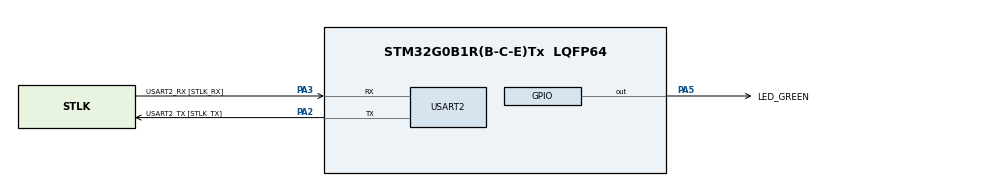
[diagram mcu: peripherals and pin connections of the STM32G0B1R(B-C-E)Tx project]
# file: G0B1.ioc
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FREERTOS.Tasks01=defaultTask,0,128,StartDefaultTask,Default,NULL,Dynamic,NULL,NULL;myTask02_Diagno,-3,128,StartTask02,Default,NULL,Dynamic,NULL,NULL;myTask03_Deferr,-3,128,StartTask03,Default,NULL,Dynamic,NULL,NULL
Mcu.Family=STM32G0
Mcu.Name=STM32G0B1R(B-C-E)Tx
Mcu.Package=LQFP64
NVIC.TIM17_FDCAN_IT1_IRQn=true\:3\:0\:false\:false\:true\:false\:true\:true\:true
NVIC.TimeBase=TIM17_FDCAN_IT1_IRQn
NVIC.TimeBaseIP=TIM17
PA13.GPIO_Label=TMS
PA13.Mode=Serial_Wire
PA13.Signal=SYS_SWDIO
PA14-BOOT0.GPIO_Label=TCK
PA14-BOOT0.Mode=Serial_Wire
PA14-BOOT0.Signal=SYS_SWCLK
PA2.GPIO_Label=USART2_TX [STLK_TX]
PA2.Mode=Asynchronous
PA2.Signal=USART2_TX
PA3.GPIO_Label=USART2_RX [STLK_RX]
PA3.Mode=Asynchronous
PA3.Signal=USART2_RX
PA5.GPIO_Label=LED_GREEN
PA5.GPIO_Speed=GPIO_SPEED_FREQ_HIGH
PA5.Signal=GPIO_Output
PC13.Mode=SYS_WakeUp1
PC13.Signal=SYS_WKUP2
PC14-OSC32_IN\ (PC14).Mode=LSE-External-Oscillator
PC14-OSC32_IN\ (PC14).Signal=RCC_OSC32_IN
PC15-OSC32_OUT\ (PC15).Mode=LSE-External-Oscillator
PC15-OSC32_OUT\ (PC15).Signal=RCC_OSC32_OUT
PF0-OSC_IN\ (PF0).GPIO_Label=MCO
PF0-OSC_IN\ (PF0).Mode=HSE-External-Clock-Source
PF0-OSC_IN\ (PF0).Signal=RCC_OSC_IN
ProjectManager.HeapSize=0x200
ProjectManager.StackSize=0x400
ProjectManager.TargetToolchain=Makefile
RCC.AHBFreq_Value=16000000
RCC.CortexFreq_Value=16000000
RCC.EXTERNAL_CLOCK_VALUE=12288000
RCC.HCLKFreq_Value=16000000
RCC.HSE_VALUE=8000000
RCC.HSI48_VALUE=48000000
RCC.HSI_VALUE=16000000
RCC.SYSCLKFreq_VALUE=16000000
RCC.USBFreq_Value=48000000
RCC.VCOOutputFreq_Value=128000000
USART2.VirtualMode-Asynchronous=VM_ASYNC
VP_FREERTOS_VS_CMSIS_V1.Mode=CMSIS_V1
VP_SYS_VS_tim17.Mode=TIM17
board=NUCLEO-G0B1RE

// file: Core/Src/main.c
/* USER CODE BEGIN Header */
/**
 ******************************************************************************
 * @file           : main.c
 * @brief          : Main program body
 ******************************************************************************
 * @attention
 *
 * Copyright (c) 2023 STMicroelectronics.
 * All rights reserved.
 *
 * This software is licensed under terms that can be found in the LICENSE file
 * in the root directory of this software component.
 * If no LICENSE file comes with this software, it is provided AS-IS.
 *
 ******************************************************************************
 */
/* USER CODE END Header */
#include "main.h"
#include "cmsis_os.h"

/* USER CODE BEGIN Includes */
#include "trice.h"
/* USER CODE END Includes */

osThreadId defaultTaskHandle;
osThreadId myTask02_DiagnoHandle;
osThreadId myTask03_DeferrHandle;
/* USER CODE BEGIN PV */
int LoopCount = 0;

/* USER CODE END PV */

void SystemClock_Config(void);
static void MX_GPIO_Init(void);
static void MX_USART2_UART_Init(void);
void StartDefaultTask(void const * argument);
void StartTask02(void const * argument);
void StartTask03(void const * argument);

int main(void)
{

  /* MCU Configuration--------------------------------------------------------*/

  /* Reset of all peripherals, Initializes the Flash interface and the Systick. */
  HAL_Init();

  /* Configure the system clock */
  SystemClock_Config();

  /* USER CODE BEGIN SysInit */
    TriceInit();

    //! This is usable as the very first trice sequence after restart. Adapt it. Use a UTF-8 capable editor like VS-Code or use pure ASCII.
    trice( "\n\n        ✨✨✨✨✨✨✨✨✨✨✨✨✨✨✨✨✨        \n        🎈🎈🎈🎈     NUCLEO-G0B1RE      🎈🎈🎈🎈\n        ✨✨✨✨✨✨✨✨✨✨✨✨✨✨✨✨✨        \n\n\n");
    TRice( "w: Hello! 👋🙂\a\n" ); // with sound!

/*
    TRICE_S( id(0), "wr:%s\n", "\n" );
    TRICE_S( id(0), "wr:%s\n", "A\n" );
    TRICE_S( id(0), "wr:%s\n", "AA\n" );
    TRICE_S( id(0), "wr:%s\n", "AAA\n" );
    TRICE_S( id(0), "wr:%s\n", "AAAA\n" );
    TRICE_S( id(0), "wr:%s\n", "AAAAA\n" );
    TRICE_S( id(0), "wr:%s\n", "AAAAAA\n" );
    TRICE_S( id(0), "wr:%s\n", "AAAAAAA\n" );
    TRICE_S( id(0), "wr:%s\n", "AAAAAAAA\n" );
    TRICE_S( id(0), "wr:%s\n", "AAAAAAAAA\n" );
    TRICE_S( id(0), "wr:%s\n", "AAAAAAAAAA\n" );
    TRICE_S( id(0), "wr:%s\n", "AAAAAAAAAAA\n" );
    TRICE_S( id(0), "wr:%s\n", "AAAAAAAAAAAA\n" );
    TRICE_S( id(0), "wr:%s\n", "AAAAAAAAAAAAA\n" );
    TRICE_S( id(0), "wr:%s\n", "AAAAAAAAAAAAAA\n" );
    TRICE_S( id(0), "wr:%s\n", "AAAAAAAAAAAAAAA\n" );
    TRICE_S( id(0), "wr:%s\n", "AAAAAAAAAAAAAAAA\n" );
    TRICE_S( id(0), "wr:%s\n", "AAAAAAAAAAAAAAAAA\n" );
    TRICE_S( id(0), "wr:%s\n", "AAAAAAAAAAAAAAAAAA\n" );
    TRICE_S( id(0), "wr:%s\n", "AAAAAAAAAAAAAAAAAAA\n" );
    TRICE_S( id(0), "wr:%s\n", "AAAAAAAAAAAAAAAAAAAA\n" );
    TRICE_S( id(0), "wr:%s\n", "AAAAAAAAAAAAAAAAAAAAA\n" );
    TRICE_S( id(0), "wr:%s\n", "AAAAAAAAAAAAAAAAAAAAAA\n" );
    TRICE_S( id(0), "wr:%s\n", "AAAAAAAAAAAAAAAAAAAAAAA\n" );
    TRICE_S( id(0), "wr:%s\n", "AAAAAAAAAAAAAAAAAAAAAAAA\n" );
    TRICE_S( id(0), "wr:%s\n", "AAAAAAAAAAAAAAAAAAAAAAAAA\n" );
    TRICE_S( id(0), "wr:%s\n", "AAAAAAAAAAAAAAAAAAAAAAAAAA\n" );
    TRICE_S( id(0), "wr:%s\n", "AAAAAAAAAAAAAAAAAAAAAAAAAAA\n" );
    TRICE_S( id(0), "wr:%s\n", "AAAAAAAAAAAAAAAAAAAAAAAAAAAA\n" );
    TRICE_S( id(0), "wr:%s\n", "AAAAAAAAAAAAAAAAAAAAAAAAAAAAA\n" );
    TRICE_S( id(0), "wr:%s\n", "AAAAAAAAAAAAAAAAAAAAAAAAAAAAAA\n" );
    TRICE_S( id(0), "wr:%s\n", "AAAAAAAAAAAAAAAAAAAAAAAAAAAAAAA\n" );
    TRICE_S( id(0), "wr:%s\n", "AAAAAAAAAAAAAAAAAAAAAAAAAAAAAAAA\n" );
    TRICE_S( id(0), "wr:%s\n", "AAAAAAAAAAAAAAAAAAAAAAAAAAAAAAAAA\n" );
    TRICE_S( id(0), "wr:%s\n", "AAAAAAAAAAAAAAAAAAAAAAAAAAAAAAAAAA\n" );
    TRICE_S( id(0), "wr:%s\n", "AAAAAAAAAAAAAAAAAAAAAAAAAAAAAAAAAAA\n" );
    TRICE_S( id(0), "wr:%s\n", "AAAAAAAAAAAAAAAAAAAAAAAAAAAAAAAAAAAA\n" );
    TRICE_S( id(0), "wr:%s\n", "AAAAAAAAAAAAAAAAAAAAAAAAAAAAAAAAAAAAA\n" );
    TRICE_S( id(0), "wr:%s\n", "AAAAAAAAAAAAAAAAAAAAAAAAAAAAAAAAAAAAAA\n" );
    TRICE_S( id(0), "wr:%s\n", "AAAAAAAAAAAAAAAAAAAAAAAAAAAAAAAAAAAAAAA\n" );
    TRICE_S( id(0), "wr:%s\n", "AAAAAAAAAAAAAAAAAAAAAAAAAAAAAAAAAAAAAAAA\n" );
    TRICE_S( id(0), "wr:%s\n", "AAAAAAAAAAAAAAAAAAAAAAAAAAAAAAAAAAAAAAAAA\n" );
    TRICE_S( id(0), "wr:%s\n", "AAAAAAAAAAAAAAAAAAAAAAAAAAAAAAAAAAAAAAAAAA\n" );
    TRICE_S( id(0), "wr:%s\n", "AAAAAAAAAAAAAAAAAAAAAAAAAAAAAAAAAAAAAAAAAAA\n" );
    TRICE_S( id(0), "wr:%s\n", "AAAAAAAAAAAAAAAAAAAAAAAAAAAAAAAAAAAAAAAAAAAA\n" );
    TRICE_S( id(0), "wr:%s\n", "AAAAAAAAAAAAAAAAAAAAAAAAAAAAAAAAAAAAAAAAAAAAA\n" );
    TRICE_S( id(0), "wr:%s\n", "AAAAAAAAAAAAAAAAAAAAAAAAAAAAAAAAAAAAAAAAAAAAAA\n" );
    TRICE_S( id(0), "wr:%s\n", "AAAAAAAAAAAAAAAAAAAAAAAAAAAAAAAAAAAAAAAAAAAAAAA\n" );
    TRICE_S( id(0), "wr:%s\n", "AAAAAAAAAAAAAAAAAAAAAAAAAAAAAAAAAAAAAAAAAAAAAAAA\n" );
    TRICE_S( id(0), "wr:%s\n", "AAAAAAAAAAAAAAAAAAAAAAAAAAAAAAAAAAAAAAAAAAAAAAAAA\n" );
    TRICE_S( id(0), "wr:%s\n", "AAAAAAAAAAAAAAAAAAAAAAAAAAAAAAAAAAAAAAAAAAAAAAAAAA\n" );
    TRICE_S( id(0), "wr:%s\n", "AAAAAAAAAAAAAAAAAAAAAAAAAAAAAAAAAAAAAAAAAAAAAAAAAAA\n" );
    TRICE_S( id(0), "wr:%s\n", "AAAAAAAAAAAAAAAAAAAAAAAAAAAAAAAAAAAAAAAAAAAAAAAAAAAA\n" );
    TRICE_S( id(0), "wr:%s\n", "AAAAAAAAAAAAAAAAAAAAAAAAAAAAAAAAAAAAAAAAAAAAAAAAAAAAA\n" );
    TRICE_S( id(0), "wr:%s\n", "AAAAAAAAAAAAAAAAAAAAAAAAAAAAAAAAAAAAAAAAAAAAAAAAAAAAAA\n" );
    TRICE_S( id(0), "wr:%s\n", "AAAAAAAAAAAAAAAAAAAAAAAAAAAAAAAAAAAAAAAAAAAAAAAAAAAAAAA\n" );
    TRICE_S( id(0), "wr:%s\n", "AAAAAAAAAAAAAAAAAAAAAAAAAAAAAAAAAAAAAAAAAAAAAAAAAAAAAAAA\n" );
    TRICE_S( id(0), "wr:%s\n", "AAAAAAAAAAAAAAAAAAAAAAAAAAAAAAAAAAAAAAAAAAAAAAAAAAAAAAAAA\n" );
    TRICE_S( id(0), "wr:%s\n", "AAAAAAAAAAAAAAAAAAAAAAAAAAAAAAAAAAAAAAAAAAAAAAAAAAAAAAAAAA\n" );
    TRICE_S( id(0), "wr:%s\n", "AAAAAAAAAAAAAAAAAAAAAAAAAAAAAAAAAAAAAAAAAAAAAAAAAAAAAAAAAAA\n" );
    TRICE_S( id(0), "wr:%s\n", "AAAAAAAAAAAAAAAAAAAAAAAAAAAAAAAAAAAAAAAAAAAAAAAAAAAAAAAAAAAA\n" );
    TRICE_S( id(0), "wr:%s\n", "AAAAAAAAAAAAAAAAAAAAAAAAAAAAAAAAAAAAAAAAAAAAAAAAAAAAAAAAAAAAA\n" );
    TRICE_S( id(0), "wr:%s\n", "AAAAAAAAAAAAAAAAAAAAAAAAAAAAAAAAAAAAAAAAAAAAAAAAAAAAAAAAAAAAAA\n" );
    TRICE_S( id(0), "wr:%s\n", "AAAAAAAAAAAAAAAAAAAAAAAAAAAAAAAAAAAAAAAAAAAAAAAAAAAAAAAAAAAAAAA\n" );
    TRICE_S( id(0), "wr:%s\n", "AAAAAAAAAAAAAAAAAAAAAAAAAAAAAAAAAAAAAAAAAAAAAAAAAAAAAAAAAAAAAAAA\n" );
    TRICE_S( id(0), "wr:%s\n", "AAAAAAAAAAAAAAAAAAAAAAAAAAAAAAAAAAAAAAAAAAAAAAAAAAAAAAAAAAAAAAAAA\n" );
    TRICE_S( id(0), "wr:%s\n", "AAAAAAAAAAAAAAAAAAAAAAAAAAAAAAAAAAAAAAAAAAAAAAAAAAAAAAAAAAAAAAAAAA\n" );
    TRICE_S( id(0), "wr:%s\n", "AAAAAAAAAAAAAAAAAAAAAAAAAAAAAAAAAAAAAAAAAAAAAAAAAAAAAAAAAAAAAAAAAAA\n" );
    TRICE_S( id(0), "wr:%s\n", "AAAAAAAAAAAAAAAAAAAAAAAAAAAAAAAAAAAAAAAAAAAAAAAAAAAAAAAAAAAAAAAAAAAA\n" );
    TRICE_S( id(0), "wr:%s\n", "AAAAAAAAAAAAAAAAAAAAAAAAAAAAAAAAAAAAAAAAAAAAAAAAAAAAAAAAAAAAAAAAAAAAA\n" );
    TRICE_S( id(0), "wr:%s\n", "AAAAAAAAAAAAAAAAAAAAAAAAAAAAAAAAAAAAAAAAAAAAAAAAAAAAAAAAAAAAAAAAAAAAAA\n" );
    TRICE_S( id(0), "wr:%s\n", "AAAAAAAAAAAAAAAAAAAAAAAAAAAAAAAAAAAAAAAAAAAAAAAAAAAAAAAAAAAAAAAAAAAAAAA\n" );
    TRICE_S( id(0), "wr:%s\n", "AAAAAAAAAAAAAAAAAAAAAAAAAAAAAAAAAAAAAAAAAAAAAAAAAAAAAAAAAAAAAAAAAAAAAAAA\n" );
    TRICE_S( id(0), "wr:%s\n", "AAAAAAAAAAAAAAAAAAAAAAAAAAAAAAAAAAAAAAAAAAAAAAAAAAAAAAAAAAAAAAAAAAAAAAAAA\n" );
    TRICE_S( id(0), "wr:%s\n", "AAAAAAAAAAAAAAAAAAAAAAAAAAAAAAAAAAAAAAAAAAAAAAAAAAAAAAAAAAAAAAAAAAAAAAAAAA\n" );
    TRICE_S( id(0), "wr:%s\n", "AAAAAAAAAAAAAAAAAAAAAAAAAAAAAAAAAAAAAAAAAAAAAAAAAAAAAAAAAAAAAAAAAAAAAAAAAAA\n" );
    TRICE_S( id(0), "wr:%s\n", "AAAAAAAAAAAAAAAAAAAAAAAAAAAAAAAAAAAAAAAAAAAAAAAAAAAAAAAAAAAAAAAAAAAAAAAAAAAA\n" );
    TRICE_S( id(0), "wr:%s\n", "AAAAAAAAAAAAAAAAAAAAAAAAAAAAAAAAAAAAAAAAAAAAAAAAAAAAAAAAAAAAAAAAAAAAAAAAAAAAA\n" );
    TRICE_S( id(0), "wr:%s\n", "AAAAAAAAAAAAAAAAAAAAAAAAAAAAAAAAAAAAAAAAAAAAAAAAAAAAAAAAAAAAAAAAAAAAAAAAAAAAAA\n" );
    TRICE_S( id(0), "wr:%s\n", "AAAAAAAAAAAAAAAAAAAAAAAAAAAAAAAAAAAAAAAAAAAAAAAAAAAAAAAAAAAAAAAAAAAAAAAAAAAAAAA\n" );
    TRICE_S( id(0), "wr:%s\n", "AAAAAAAAAAAAAAAAAAAAAAAAAAAAAAAAAAAAAAAAAAAAAAAAAAAAAAAAAAAAAAAAAAAAAAAAAAAAAAA\n" );
    TRICE_S( id(0), "wr:%s\n", "AAAAAAAAAAAAAAAAAAAAAAAAAAAAAAAAAAAAAAAAAAAAAAAAAAAAAAAAAAAAAAAAAAAAAAAAAAAAAAAA\n" );
    TRICE_S( id(0), "wr:%s\n", "AAAAAAAAAAAAAAAAAAAAAAAAAAAAAAAAAAAAAAAAAAAAAAAAAAAAAAAAAAAAAAAAAAAAAAAAAAAAAAAAA\n" );
    TRICE_S( id(0), "wr:%s\n", "AAAAAAAAAAAAAAAAAAAAAAAAAAAAAAAAAAAAAAAAAAAAAAAAAAAAAAAAAAAAAAAAAAAAAAAAAAAAAAAAAA\n" );
    TRICE_S( id(0), "wr:%s\n", "AAAAAAAAAAAAAAAAAAAAAAAAAAAAAAAAAAAAAAAAAAAAAAAAAAAAAAAAAAAAAAAAAAAAAAAAAAAAAAAAAAA\n" );
    TRICE_S( id(0), "wr:%s\n", "AAAAAAAAAAAAAAAAAAAAAAAAAAAAAAAAAAAAAAAAAAAAAAAAAAAAAAAAAAAAAAAAAAAAAAAAAAAAAAAAAAAA\n" );
    TRICE_S( id(0), "wr:%s\n", "AAAAAAAAAAAAAAAAAAAAAAAAAAAAAAAAAAAAAAAAAAAAAAAAAAAAAAAAAAAAAAAAAAAAAAAAAAAAAAAAAAAAA\n" );
    TRICE_S( id(0), "wr:%s\n", "AAAAAAAAAAAAAAAAAAAAAAAAAAAAAAAAAAAAAAAAAAAAAAAAAAAAAAAAAAAAAAAAAAAAAAAAAAAAAAAAAAAAAA\n" );
    TRICE_S( id(0), "wr:%s\n", "AAAAAAAAAAAAAAAAAAAAAAAAAAAAAAAAAAAAAAAAAAAAAAAAAAAAAAAAAAAAAAAAAAAAAAAAAAAAAAAAAAAAAAA\n" );
    TRICE_S( id(0), "wr:%s\n", "AAAAAAAAAAAAAAAAAAAAAAAAAAAAAAAAAAAAAAAAAAAAAAAAAAAAAAAAAAAAAAAAAAAAAAAAAAAAAAAAAAAAAAAA\n" );
    TRICE_S( id(0), "wr:%s\n", "AAAAAAAAAAAAAAAAAAAAAAAAAAAAAAAAAAAAAAAAAAAAAAAAAAAAAAAAAAAAAAAAAAAAAAAAAAAAAAAAAAAAAAAAA\n" );
    TRICE_S( id(0), "wr:%s\n", "AAAAAAAAAAAAAAAAAAAAAAAAAAAAAAAAAAAAAAAAAAAAAAAAAAAAAAAAAAAAAAAAAAAAAAAAAAAAAAAAAAAAAAAAAA\n" );
    TRICE_S( id(0), "wr:%s\n", "AAAAAAAAAAAAAAAAAAAAAAAAAAAAAAAAAAAAAAAAAAAAAAAAAAAAAAAAAAAAAAAAAAAAAAAAAAAAAAAAAAAAAAAAAAA\n" );
    TRICE_S( id(0), "wr:%s\n", "AAAAAAAAAAAAAAAAAAAAAAAAAAAAAAAAAAAAAAAAAAAAAAAAAAAAAAAAAAAAAAAAAAAAAAAAAAAAAAAAAAAAAAAAAAAA\n" );
    TRICE_S( id(0), "wr:%s\n", "AAAAAAAAAAAAAAAAAAAAAAAAAAAAAAAAAAAAAAAAAAAAAAAAAAAAAAAAAAAAAAAAAAAAAAAAAAAAAAAAAAAAAAAAAAAAA\n" );
    TRICE_S( id(0), "wr:%s\n", "AAAAAAAAAAAAAAAAAAAAAAAAAAAAAAAAAAAAAAAAAAAAAAAAAAAAAAAAAAAAAAAAAAAAAAAAAAAAAAAAAAAAAAAAAAAAAA\n" );
    TRICE_S( id(0), "wr:%s\n", "AAAAAAAAAAAAAAAAAAAAAAAAAAAAAAAAAAAAAAAAAAAAAAAAAAAAAAAAAAAAAAAAAAAAAAAAAAAAAAAAAAAAAAAAAAAAAAA\n" );
    TRICE_S( id(0), "wr:%s\n", "AAAAAAAAAAAAAAAAAAAAAAAAAAAAAAAAAAAAAAAAAAAAAAAAAAAAAAAAAAAAAAAAAAAAAAAAAAAAAAAAAAAAAAAAAAAAAAAA\n" );
    TRICE_S( id(0), "wr:%s\n", "AAAAAAAAAAAAAAAAAAAAAAAAAAAAAAAAAAAAAAAAAAAAAAAAAAAAAAAAAAAAAAAAAAAAAAAAAAAAAAAAAAAAAAAAAAAAAAAAA\n" );
    TRICE_S( id(0), "wr:%s\n", "AAAAAAAAAAAAAAAAAAAAAAAAAAAAAAAAAAAAAAAAAAAAAAAAAAAAAAAAAAAAAAAAAAAAAAAAAAAAAAAAAAAAAAAAAAAAAAAAAA\n" );
    TRICE_S( id(0), "wr:%s\n", "AAAAAAAAAAAAAAAAAAAAAAAAAAAAAAAAAAAAAAAAAAAAAAAAAAAAAAAAAAAAAAAAAAAAAAAAAAAAAAAAAAAAAAAAAAAAAAAAAAA\n" );
    TRICE_S( id(0), "wr:%s\n", "AAAAAAAAAAAAAAAAAAAAAAAAAAAAAAAAAAAAAAAAAAAAAAAAAAAAAAAAAAAAAAAAAAAAAAAAAAAAAAAAAAAAAAAAAAAAAAAAAAAA\n" );
    TRICE_S( id(0), "wr:%s\n", "AAAAAAAAAAAAAAAAAAAAAAAAAAAAAAAAAAAAAAAAAAAAAAAAAAAAAAAAAAAAAAAAAAAAAAAAAAAAAAAAAAAAAAAAAAAAAAAAAAAAA\n" );
    TRICE_S( id(0), "wr:%s\n", "AAAAAAAAAAAAAAAAAAAAAAAAAAAAAAAAAAAAAAAAAAAAAAAAAAAAAAAAAAAAAAAAAAAAAAAAAAAAAAAAAAAAAAAAAAAAAAAAAAAAAA\n" );
    TRICE_S( id(0), "wr:%s\n", "AAAAAAAAAAAAAAAAAAAAAAAAAAAAAAAAAAAAAAAAAAAAAAAAAAAAAAAAAAAAAAAAAAAAAAAAAAAAAAAAAAAAAAAAAAAAAAAAAAAAAAA\n" );
    TRICE_S( id(0), "wr:%s\n", "AAAAAAAAAAAAAAAAAAAAAAAAAAAAAAAAAAAAAAAAAAAAAAAAAAAAAAAAAAAAAAAAAAAAAAAAAAAAAAAAAAAAAAAAAAAAAAAAAAAAAAAA\n" );
    TRICE_S( id(0), "wr:%s\n", "AAAAAAAAAAAAAAAAAAAAAAAAAAAAAAAAAAAAAAAAAAAAAAAAAAAAAAAAAAAAAAAAAAAAAAAAAAAAAAAAAAAAAAAAAAAAAAAAAAAAAAAAA\n" );
    TRICE_S( id(0), "wr:%s\n", "AAAAAAAAAAAAAAAAAAAAAAAAAAAAAAAAAAAAAAAAAAAAAAAAAAAAAAAAAAAAAAAAAAAAAAAAAAAAAAAAAAAAAAAAAAAAAAAAAAAAAAAAAA\n" );
    TRICE_S( id(0), "wr:%s\n", "AAAAAAAAAAAAAAAAAAAAAAAAAAAAAAAAAAAAAAAAAAAAAAAAAAAAAAAAAAAAAAAAAAAAAAAAAAAAAAAAAAAAAAAAAAAAAAAAAAAAAAAAAAA\n" );
    TRICE_S( id(0), "wr:%s\n", "AAAAAAAAAAAAAAAAAAAAAAAAAAAAAAAAAAAAAAAAAAAAAAAAAAAAAAAAAAAAAAAAAAAAAAAAAAAAAAAAAAAAAAAAAAAAAAAAAAAAAAAAAAAA\n" );
    TRICE_S( id(0), "wr:%s\n", "AAAAAAAAAAAAAAAAAAAAAAAAAAAAAAAAAAAAAAAAAAAAAAAAAAAAAAAAAAAAAAAAAAAAAAAAAAAAAAAAAAAAAAAAAAAAAAAAAAAAAAAAAAAAA\n" );
    TRICE_S( id(0), "wr:%s\n", "AAAAAAAAAAAAAAAAAAAAAAAAAAAAAAAAAAAAAAAAAAAAAAAAAAAAAAAAAAAAAAAAAAAAAAAAAAAAAAAAAAAAAAAAAAAAAAAAAAAAAAAAAAAAAA\n" );
    TRICE_S( id(0), "wr:%s\n", "AAAAAAAAAAAAAAAAAAAAAAAAAAAAAAAAAAAAAAAAAAAAAAAAAAAAAAAAAAAAAAAAAAAAAAAAAAAAAAAAAAAAAAAAAAAAAAAAAAAAAAAAAAAAAAA\n" );
    TRICE_S( id(0), "wr:%s\n", "AAAAAAAAAAAAAAAAAAAAAAAAAAAAAAAAAAAAAAAAAAAAAAAAAAAAAAAAAAAAAAAAAAAAAAAAAAAAAAAAAAAAAAAAAAAAAAAAAAAAAAAAAAAAAAAA\n" );
    TRICE_S( id(0), "wr:%s\n", "AAAAAAAAAAAAAAAAAAAAAAAAAAAAAAAAAAAAAAAAAAAAAAAAAAAAAAAAAAAAAAAAAAAAAAAAAAAAAAAAAAAAAAAAAAAAAAAAAAAAAAAAAAAAAAAAA\n" );

    TRICE_S( id(0), "wr:%s\n", "AAAAAAAAAAAAAAAAAAAAAAAAAAAAAAAAAAAAAAAAAAAAAAAAAAAAAAAAAAAAAAAAAAAAAAAAAAAAAAAAAAAAAAAAAAAAAAAAAAAAAAAAAAAAAAAAAA\n" );
    TRICE_S( id(0), "wr:%s\n", "AAAAAAAAAAAAAAAAAAAAAAAAAAAAAAAAAAAAAAAAAAAAAAAAAAAAAAAAAAAAAAAAAAAAAAAAAAAAAAAAAAAAAAAAAAAAAAAAAAAAAAAAAAAAAAAAAAA\n" );
    */
    TRice( "w: Hello! 👋🙂\a\n" ); // with sound!
    TRice8( "w: Hello! 👋🙂 %d\n", 1 );
    Trice8( "w: Hello! 👋🙂 %d %d\a\n", 1, 2 );
    Trice8( "w: Hello! 👋🙂 %d %d %d\a\n", 1, 2, 3 );
    trice( "w: Hello! 👋🙂 %f (default rounded float)\n",                                          aFloat( 2.71828182845904523536 ) );
    trice( "w: Hello! 👋🙂 %.20f (float with more ciphers but not increased precision)\n",         aFloat( 2.71828182845904523536 ) );
    trice64( "w: Hello! 👋🙂 %.20f (double with more but limited precision but it is limited)\n", aDouble( 2.71828182845904523536 ) );
                                                                                    trice( "w: Hello! 👋🙂 2.71828182845904523536 (the full number as string)\n" );
  /* USER CODE END SysInit */

  /* Initialize all configured peripherals */
  MX_GPIO_Init();
  MX_USART2_UART_Init();

  /* Create the thread(s) */
  /* definition and creation of defaultTask */
  osThreadDef(defaultTask, StartDefaultTask, osPriorityNormal, 0, 128);
  defaultTaskHandle = osThreadCreate(osThread(defaultTask), NULL);

  /* definition and creation of myTask02_Diagno */
  osThreadDef(myTask02_Diagno, StartTask02, osPriorityIdle, 0, 128);
  myTask02_DiagnoHandle = osThreadCreate(osThread(myTask02_Diagno), NULL);

  /* definition and creation of myTask03_Deferr */
  osThreadDef(myTask03_Deferr, StartTask03, osPriorityIdle, 0, 128);
  myTask03_DeferrHandle = osThreadCreate(osThread(myTask03_Deferr), NULL);

  /* Start scheduler */
  osKernelStart();

  /* We should never get here as control is now taken by the scheduler */

  /* Infinite loop */
  while (1)
  {

  }
}

void SystemClock_Config(void)
{
  /* HSI configuration and activation */
  LL_RCC_HSI_Enable();
  while(LL_RCC_HSI_IsReady() != 1)
  {
  }

  /* Set AHB prescaler*/
  LL_RCC_SetAHBPrescaler(LL_RCC_SYSCLK_DIV_1);

  /* Sysclk activation on the HSI */
  LL_RCC_SetSysClkSource(LL_RCC_SYS_CLKSOURCE_HSI);
  while(LL_RCC_GetSysClkSource() != LL_RCC_SYS_CLKSOURCE_STATUS_HSI)
  {
  }

  /* Set APB1 prescaler*/
  LL_RCC_SetAPB1Prescaler(LL_RCC_APB1_DIV_1);
  /* Update CMSIS variable (which can be updated also through SystemCoreClockUpdate function) */
  LL_SetSystemCoreClock(16000000);

   /* Update the time base */
  if (HAL_InitTick (TICK_INT_PRIORITY) != HAL_OK)
  {
    Error_Handler();
  }
}

static void MX_USART2_UART_Init(void)
{

  LL_USART_InitTypeDef USART_InitStruct = {0};

  LL_GPIO_InitTypeDef GPIO_InitStruct = {0};

  LL_RCC_SetUSARTClockSource(LL_RCC_USART2_CLKSOURCE_PCLK1);

  /* Peripheral clock enable */
  LL_APB1_GRP1_EnableClock(LL_APB1_GRP1_PERIPH_USART2);

  LL_IOP_GRP1_EnableClock(LL_IOP_GRP1_PERIPH_GPIOA);
  /**USART2 GPIO Configuration
  PA2   ------> USART2_TX
  PA3   ------> USART2_RX
  */
  GPIO_InitStruct.Pin = USART2_TX_Pin;
  GPIO_InitStruct.Mode = LL_GPIO_MODE_ALTERNATE;
  GPIO_InitStruct.Speed = LL_GPIO_SPEED_FREQ_LOW;
  GPIO_InitStruct.OutputType = LL_GPIO_OUTPUT_PUSHPULL;
  GPIO_InitStruct.Pull = LL_GPIO_PULL_NO;
  GPIO_InitStruct.Alternate = LL_GPIO_AF_1;
  LL_GPIO_Init(USART2_TX_GPIO_Port, &GPIO_InitStruct);

  GPIO_InitStruct.Pin = USART2_RX_Pin;
  GPIO_InitStruct.Mode = LL_GPIO_MODE_ALTERNATE;
  GPIO_InitStruct.Speed = LL_GPIO_SPEED_FREQ_LOW;
  GPIO_InitStruct.OutputType = LL_GPIO_OUTPUT_PUSHPULL;
  GPIO_InitStruct.Pull = LL_GPIO_PULL_NO;
  GPIO_InitStruct.Alternate = LL_GPIO_AF_1;
  LL_GPIO_Init(USART2_RX_GPIO_Port, &GPIO_InitStruct);

  USART_InitStruct.PrescalerValue = LL_USART_PRESCALER_DIV1;
  USART_InitStruct.BaudRate = 115200;
  USART_InitStruct.DataWidth = LL_USART_DATAWIDTH_8B;
  USART_InitStruct.StopBits = LL_USART_STOPBITS_1;
  USART_InitStruct.Parity = LL_USART_PARITY_NONE;
  USART_InitStruct.TransferDirection = LL_USART_DIRECTION_TX_RX;
  USART_InitStruct.HardwareFlowControl = LL_USART_HWCONTROL_NONE;
  USART_InitStruct.OverSampling = LL_USART_OVERSAMPLING_16;
  LL_USART_Init(USART2, &USART_InitStruct);
  LL_USART_SetTXFIFOThreshold(USART2, LL_USART_FIFOTHRESHOLD_1_8);
  LL_USART_SetRXFIFOThreshold(USART2, LL_USART_FIFOTHRESHOLD_1_8);
  LL_USART_DisableFIFO(USART2);
  LL_USART_ConfigAsyncMode(USART2);

  LL_USART_Enable(USART2);

  /* Polling USART2 initialisation */
  while((!(LL_USART_IsActiveFlag_TEACK(USART2))) || (!(LL_USART_IsActiveFlag_REACK(USART2))))
  {
  }

}

static void MX_GPIO_Init(void)
{
  LL_GPIO_InitTypeDef GPIO_InitStruct = {0};

  /* GPIO Ports Clock Enable */
  LL_IOP_GRP1_EnableClock(LL_IOP_GRP1_PERIPH_GPIOC);
  LL_IOP_GRP1_EnableClock(LL_IOP_GRP1_PERIPH_GPIOF);
  LL_IOP_GRP1_EnableClock(LL_IOP_GRP1_PERIPH_GPIOA);

  /**/
  LL_GPIO_ResetOutputPin(LED_GREEN_GPIO_Port, LED_GREEN_Pin);

  /**/
  GPIO_InitStruct.Pin = LED_GREEN_Pin;
  GPIO_InitStruct.Mode = LL_GPIO_MODE_OUTPUT;
  GPIO_InitStruct.Speed = LL_GPIO_SPEED_FREQ_HIGH;
  GPIO_InitStruct.OutputType = LL_GPIO_OUTPUT_PUSHPULL;
  GPIO_InitStruct.Pull = LL_GPIO_PULL_NO;
  LL_GPIO_Init(LED_GREEN_GPIO_Port, &GPIO_InitStruct);

}

void StartDefaultTask(void const * argument)
{
  /* USER CODE BEGIN 5 */
  TRice( "msg:StartDefaultTask\n" );
  /* Infinite loop */
  for(;;)
  {
    static int i = 50;
    if( i++ > 330 ){
      i = 50;
    }
    TriceCheck( i ); // this generates trice data

    osDelay(100);
  }
  /* USER CODE END 5 */
}

void StartTask02(void const * argument)
{
  /* USER CODE BEGIN StartTask02 */
  /* Infinite loop */
  for(;;)
  {
    void TriceLogDiagnosticValues( void );
    TriceLogDiagnosticValues();
    osDelay(10000);
  }
  /* USER CODE END StartTask02 */
}

void StartTask03(void const * argument)
{
  /* USER CODE BEGIN StartTask03 */
  /* Infinite loop */
  for(;;)
  {
    TriceTransfer(); // Needed only for deferred output.
    osDelay(100);
  }
  /* USER CODE END StartTask03 */
}

void HAL_TIM_PeriodElapsedCallback(TIM_HandleTypeDef *htim)
{
  /* USER CODE BEGIN Callback 0 */
  //TRice( "att:HAL_TIM_PeriodElapsedCallback\n");
  /* USER CODE END Callback 0 */
  if (htim->Instance == TIM17) {
    HAL_IncTick();
  }
}

void Error_Handler(void)
{
  __disable_irq();
  while (1)
  {
  }
}
